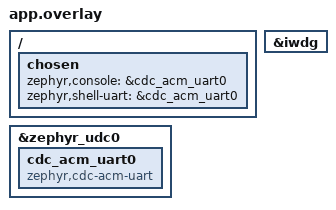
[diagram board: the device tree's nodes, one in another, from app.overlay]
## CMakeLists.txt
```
cmake_minimum_required(VERSION 3.20.0)

find_package(Zephyr REQUIRED HINTS $ENV{ZEPHYR_BASE})
project(my_zephyr_app)

target_sources(app PRIVATE src/watchdogtimer_event.c)
```

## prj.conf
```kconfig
CONFIG_LOG=y
CONFIG_ZBUS_LOG_LEVEL_INF=y

CONFIG_THREAD_NAME=y

CONFIG_USB_DEVICE_STACK=y
CONFIG_USB_DEVICE_INITIALIZE_AT_BOOT=y
CONFIG_SERIAL=y
CONFIG_CONSOLE=y

CONFIG_UART_CONSOLE=y
CONFIG_UART_LINE_CTRL=y
CONFIG_ZBUS=y
CONFIG_WATCHDOG=y
CONFIG_TASK_WDT=y
CONFIG_TASK_WDT_CHANNELS=3
CONFIG_LOG_RATELIMIT=y
CONFIG_LOG_RATELIMIT_INTERVAL_MS=1000

CONFIG_SHELL=y
CONFIG_KERNEL_SHELL=y

CONFIG_THREAD_MONITOR=y
CONFIG_THREAD_NAME=y
# Enable DTR check so shell waits for terminal to connect
CONFIG_SHELL_BACKEND_SERIAL_CHECK_DTR=y
CONFIG_TRACING=y
CONFIG_TRACING_CTF=y
CONFIG_TRACING_ASYNC=y
CONFIG_TRACING_BACKEND_RAM=y
```

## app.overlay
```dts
/{
	chosen {
	zephyr,console = &cdc_acm_uart0;
        zephyr,shell-uart =&cdc_acm_uart0;
	};
};

&zephyr_udc0{
	status="okay";
	cdc_acm_uart0: cdc_acm_uart0{
	compatible ="zephyr,cdc-acm-uart";
	};
};
&iwdg {
    status = "okay";
};
```

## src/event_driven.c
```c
#include<zephyr/kernel.h>
#include<zephyr/logging/log.h>
#include<zephyr/zbus/zbus.h>


LOG_MODULE_REGISTER(task4,LOG_LEVEL_INF);

#define STACK_SIZE        2048U
#define SENSOR_PERIOD_MS   100U
#define SENSOR_COUNT       18
#define TEMP_ALARM_MC   27000

struct sensor_data{
    int32_t temperature_mc;
    int32_t timestamp_ms;
};

static void display_listener_cb(const struct zbus_channel *chan);
/*listener*/
ZBUS_LISTENER_DEFINE(display_lis,display_listener_cb);
/*for the slow logging*/
ZBUS_SUBSCRIBER_DEFINE(alarm_sub,9);
ZBUS_CHAN_DEFINE(sensor_chan,
    struct sensor_data,
    NULL,
    NULL,
    ZBUS_OBSERVERS(display_lis,alarm_sub),
    ZBUS_MSG_INIT(.temperature_mc=0,
        .timestamp_ms=0,
    ));
static void display_listener_cb(const struct zbus_channel *chan){
    const struct sensor_data *msg= (const struct sensor_data *)zbus_chan_const_msg(chan);

   LOG_INF("[DISPLAY-LIS] thread=%s  temp=%d mC",
            k_thread_name_get(k_current_get()),
            msg->temperature_mc);
    
}

static void sensor_thread_fn(void *p1,void *p2,void *p3){
    ARG_UNUSED(p1);ARG_UNUSED(p2);ARG_UNUSED(p3);
    k_thread_name_set(k_current_get(),"sensor");
 for (int i = 0; i < SENSOR_COUNT; i++) {
        struct sensor_data data = {
            .temperature_mc = 24000 + (i * 350),
            .timestamp_ms = k_uptime_get_32(),
        };

        LOG_INF("[SENSOR] publish  temp=%d mC",
                data.temperature_mc);

        int ret = zbus_chan_pub(&sensor_chan, &data, K_MSEC(100));
        if (ret != 0) {
            LOG_WRN("[SENSOR] publish failed ret=%d", ret);
        }

        k_msleep(SENSOR_PERIOD_MS);
    }

    LOG_INF("[SENSOR] done");
}

/*sensor alarm**/

static void alarm_thread_fn(void *p1,void *p2,void *p3){
    ARG_UNUSED(p1);ARG_UNUSED(p2);ARG_UNUSED(p3);
    k_thread_name_set(k_current_get(),"alarm");
    const struct zbus_channel*chan=NULL;
    int alarms=0;
    while(true){
      int ret = zbus_sub_wait(&alarm_sub, &chan, K_MSEC(3000));
        if (ret != 0) {
            LOG_INF("[ALARM-SUB] timeout, done");
            break;
        }

        struct sensor_data msg;

        ret = zbus_chan_read(chan, &msg, K_MSEC(100));
        if (ret != 0) {
            LOG_WRN("[ALARM-SUB] read failed ret=%d", ret);
            continue;
        }

        if (msg.temperature_mc >= TEMP_ALARM_MC) {
            alarms++;

            LOG_WRN("[ALARM-SUB] HIGH TEMP  temp=%d mC alarms=%d",
                    msg.temperature_mc,
                    alarms);
        } else {
            LOG_INF("[ALARM-SUB] ok temp=%d mC",
                    msg.temperature_mc);
        }  
      }
}
K_THREAD_DEFINE(sensor_thread, STACK_SIZE, sensor_thread_fn,
                NULL, NULL, NULL, 5, 0, 0);


K_THREAD_DEFINE(alarm_thread, STACK_SIZE, alarm_thread_fn,
                NULL, NULL, NULL, 6, 0, 0);
                int main(void)
{
    LOG_INF("=== L4 Demo 2: Zbus Pub-Sub ===");
    LOG_INF("sensor publishes every %dms", SENSOR_PERIOD_MS);
    LOG_INF("display listener runs in publisher context");
    LOG_INF("logger uses message subscriber copies");
    LOG_INF("alarm uses a regular subscriber");
    LOG_INF("alarm threshold: %d mC", TEMP_ALARM_MC);

    return 0;
}
```

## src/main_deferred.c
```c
#include<zephyr/kernel.h>
#include<zephyr/logging/log.h>

LOG_MODULE_REGISTER(task3_work1,LOG_LEVEL_INF);
#define STACK_SIZE 1024U
#define SENSOR_MS 100U

static void sensor_work_handler(struct k_work *work){
    LOG_INF("WORK HANDLER EXCUTED,EVENT HAPPEND");
}
K_WORK_DEFINE(sensor_work,sensor_work_handler);
static void sensor_sim_fn(void *p1,void *p2,void *p3){
    while(1){
        LOG_INF("SENSOR FIRED :SUMMBITING THE WORK TO THE SYSTEM WORKQUEUE");
        k_work_submit(&sensor_work);
        /*
        k_work_reschedule(&sensor_debounce_work, K_MSEC(20));
        */
        k_msleep(SENSOR_MS);
    }
}
K_THREAD_DEFINE(sensor_thread, STACK_SIZE, sensor_sim_fn, NULL, NULL, NULL, 5, 0, 0);

int main(void) {
    LOG_INF("=== L3 Homework: Workqueue Solution ===");
    return 0;
}
```

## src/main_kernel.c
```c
#include<zephyr.h>
#include <zephyr/kernel.h>
#include <zephyr/logging/log.h>

LOG_MODULE_REGISTER(demo_kernel, LOG_LEVEL_INF);

#define STACK_SIZE 1024

#define PRIO_A 7
#define PRIO_B 5
#define PRIO_C 3
#define PRIO_D -1
void t_low_fn(void *p1, void *p2, void *p3)
{
    while (1) {
        LOG_INF("T_LOW RUNNING");
        k_msleep(300);
    }
}

void t_med_fn(void *p1, void *p2, void *p3)
{
    while (1) {
        LOG_INF("T_MED_RUNNING");
        k_msleep(200);
    }
}
void t_high_fn(void *p1, void *p2, void *p3)
{
    while (1) {
        LOG_INF("T_HIGH_RUNNING");
        k_msleep(100);
    }
}

void t_cooperative_fn(void *p1,void *p2,void *p3){
    while(1){
        int count=0;
        while(count<=5){
            LOG_INF("T_COOPERATIVE_RUNNING");
            count++;
        }
     LOG_INF("TASK COMPLETED BY THE COOPERATIVE THREAD");
     k_yield();

    }
}
/***
 *  when k_yield() is called, the scheduler looks for another "Ready" thread of equal or higher priority to hand the CPU to.
 *  Since -1 is the highest priority in your system, it instantly hands the CPU right back to
 *  the cooperative thread, locking up the system
 */
K_THREAD_DEFINE(thread_a, STACK_SIZE, t_low_fn,
                NULL, NULL, NULL, PRIO_A, 0, 0);
K_THREAD_DEFINE(thread_b, STACK_SIZE, t_med_fn,
                NULL, NULL, NULL, PRIO_B, 0, 0);
K_THREAD_DEFINE(thread_c,STACK_SIZE,t_high_fn,
                NULL,NULL,NULL,PRIO_C,0,0);
K_THREAD_DEFINE(thread_d,STACK_SIZE,t_cooperative_fn,
                NULL,NULL,NULL,PRIO_D,0,0);

int main(void){  
    LOG_INF("MAIN BOOT:RTOS SCHEDULER HAS STARTED !");

    return 0;
}
```

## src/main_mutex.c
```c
#include <zephyr/kernel.h>
#include <zephyr/logging/log.h>

LOG_MODULE_REGISTER(race_demo,LOG_LEVEL_INF);

int bank_balance=100;
K_MUTEX_DEFINE(bank_mutex);
void thread_a_entry(void){
    while(1){
        k_mutex_lock(&bank_mutex,K_FOREVER);

        LOG_INF("Thread A :READING BALANCE");
        int local_copy = bank_balance;
        local_copy = local_copy+50;
        k_msleep(100);
        bank_balance =local_copy;
        LOG_INF("THREAD A : DEPOSITED 50 ,FINAL BALANCE %d",bank_balance);
        k_mutex_unlock(&bank_mutex);
        k_msleep(2000);
    }
}

void thread_b_entry(void){
    while(1){
        k_msleep(50);
        k_mutex_lock(&bank_mutex,K_FOREVER);
        LOG_WRN("THREAD B : READING BALANCE....");
        int local_copy =bank_balance;
        local_copy=local_copy+20;
        bank_balance=local_copy;
        LOG_WRN("Thread B: Deposited $20. Final Balance: $%d", bank_balance);
        k_mutex_unlock(&bank_mutex);
        k_msleep(2000);
    }
}

K_THREAD_DEFINE(tid_a,1024,thread_a_entry,NULL,NULL,NULL,7,0,0);
K_THREAD_DEFINE(tid_b,1024,thread_b_entry,NULL,NULL,NULL,7,0,0);

int main(void){
    return 0;
}
```

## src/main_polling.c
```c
#include <zephyr/logging/log.h>
#include <stdbool.h>

LOG_MODULE_REGISTER(task3,LOG_LEVEL_INF);
K_SEM_DEFINE(my_sem,1,1);

#define STACK_SIZE 1024U
#define SENSOR_MS 100U
#define POLL_MS 10U
#define EVENT_COUNT 10U

static volatile bool sensor_flag = false;
static int wasted_wakeups = 0;

static void sensor_sim_fn(void *p1, void *p2,void *p3){
    while(1){
        k_sem_take(&my_sem,K_FOREVER);
        sensor_flag=true;
        k_sem_give(&my_sem);
        LOG_INF("THE FLAG IS SET AND SEM IS GIVEN");
        k_msleep(SENSOR_MS);
    }
}

static void polling_fn(void *p1, void *p2, void *p3) {
    bool current_flag;

    while(1) {
        /* Take semaphore to safely read and clear the flag */
        k_sem_take(&my_sem, K_FOREVER);
        
        current_flag = sensor_flag;
        if (current_flag == true) {
            sensor_flag = false;
        }
        
        /* ALWAYS give the semaphore back */
        k_sem_give(&my_sem);

        /* Process outside the lock to minimize blocking */
        if (current_flag) {
            LOG_INF("POLLING: Event processed. (Wasted wakeups since last event: %d)", wasted_wakeups);
            wasted_wakeups = 0;
        } else {
            wasted_wakeups++;
        }
        
        k_msleep(POLL_MS);
    }
}

K_THREAD_DEFINE(sensor_thread,  STACK_SIZE, sensor_sim_fn, NULL, NULL, NULL, 5, 0, 0);
K_THREAD_DEFINE(polling_thread, STACK_SIZE, polling_fn,    NULL, NULL, NULL, 5, 0, 0);int main(void)
{
    LOG_INF("=== L3 Homework: Polling to Workqueue ===");
    LOG_INF("Starter: polling every %dms, sensor fires every %dms",
            POLL_MS, SENSOR_MS);
    LOG_INF("Expected wasted wakeups: ~%d per event",
            (SENSOR_MS / POLL_MS) - 1);
    LOG_INF("Run this, count wakeups, then convert to workqueue.");

    /* Wait long enough for all events to complete */
    

    return 0;
}
```

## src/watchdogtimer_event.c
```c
#include <zephyr/kernel.h>
#include <zephyr/task_wdt/task_wdt.h>
#include <zephyr/drivers/watchdog.h>
#include <zephyr/logging/log.h>
#include <zephyr/zbus/zbus.h>
#include <zephyr/tracing/tracing.h>




LOG_MODULE_REGISTER(pipeline_test, LOG_LEVEL_INF); /* Added semicolon */

#define QUEUE_SIZE 8
#define WDT_TIMEOUT_MS 2000
#define DEADLINE_MS 50

struct pipeline_data {
    int value;
    uint32_t timestamps_ms;
};
K_MSGQ_DEFINE(consumer_queue, sizeof(struct pipeline_data), QUEUE_SIZE, 4);

void zbus_listener_callback(const struct zbus_channel *chan) {
    /* Bug 1 Fix: use zbus_chan_const_msg() directly — avoids corrupting the
     * pointer by passing &received_data (address of a pointer) into
     * zbus_chan_read(), which overwrote it with raw bytes causing
     * garbage latency (281162 ms) and corrupted SEQ numbers. */
    const struct pipeline_data *msg = zbus_chan_const_msg(chan);
    if (k_msgq_put(&consumer_queue, msg, K_NO_WAIT) != 0) {
        LOG_WRN("Consumer Inbox FULL! Dropping data: %d", msg->value);
    }
}
ZBUS_LISTENER_DEFINE(pipeline_listener, zbus_listener_callback);

ZBUS_CHAN_DEFINE(sensor_data_chan,
                 struct pipeline_data,
                 NULL,
                 NULL,
                 ZBUS_OBSERVERS(pipeline_listener), /* Fixed: Added 'S' */
                 ZBUS_MSG_INIT(0)
);

void wdt_callback(int channel_id, void *user_data) {
    LOG_ERR("FATAL: WATCHDOG TIMER EXPIRED, CHANNEL ID %d is unresponsive", channel_id);
    LOG_ERR("SYSTEM WILL NOW HARDWARE REBOOT");
}

void producer_thread(void) {
    struct pipeline_data data = { .value = 0,.timestamps_ms=0 };
    while(1) {
        data.timestamps_ms=k_uptime_get_32();
        zbus_chan_pub(&sensor_data_chan, &data, K_NO_WAIT);
        LOG_INF("event_ready seq= %d ,queue =%u", data.value,k_msgq_num_used_get(&consumer_queue));
        sys_trace_named_event("event_ready",data.value,k_msgq_num_used_get(&consumer_queue));
        data.value++;
        k_msleep(200);
    }
}

void consumer_thread(void) {
    struct pipeline_data data_in={0}; /* Fixed: struct typo */
    int process_count = 0;
    static uint32_t deadline_miss=0;

    int wdt_channel = task_wdt_add(WDT_TIMEOUT_MS, wdt_callback, NULL);
    if(wdt_channel < 0) {
        LOG_ERR("FAILED TO ADD TASK WDT CHANNEL");
        return;
    }
    
  while (1) {
        if (k_msgq_get(&consumer_queue, &data_in, K_MSEC(100)) == 0) {
            uint32_t latency_ms = k_uptime_get_32() - data_in.timestamps_ms;

            if (latency_ms > DEADLINE_MS) {
                deadline_miss++;
                LOG_WRN_RATELIMIT("deadline_miss count=%u, SEQ=%d, latency_ms=%u",
                                  deadline_miss, data_in.value, latency_ms);
            } else {
                LOG_INF("event_done seq=%d latency_ms=%u result=OK", 
                        data_in.value, latency_ms);
                        sys_trace_named_event("event_done", data_in.value, latency_ms);
                process_count++;
            }
        }

        /* Feed the watchdog to prove this thread is not frozen */
        task_wdt_feed(wdt_channel);

        /* SIMULATE A STUCK CONSUMER */
        if (process_count == 600) {
            LOG_WRN("Simulating a catastrophic consumer freeze...");
            k_msleep(10000); 
        }
    }
}

void health_thread(void) {
    while(1) {
        uint32_t used = k_msgq_num_used_get(&consumer_queue);
        if (used >= (QUEUE_SIZE * 3 / 4)) {
            LOG_WRN("QUEUE CAPACITY IS CRITICAL %d filled", used);
        }
        k_msleep(500);
    }
}

K_THREAD_DEFINE(prod_id, 1024, (k_thread_entry_t)producer_thread, NULL, NULL, NULL, 5, 0, 0);
K_THREAD_DEFINE(cons_id, 1024, (k_thread_entry_t)consumer_thread, NULL, NULL, NULL, 5, 0, 0);
K_THREAD_DEFINE(hlth_id, 1024, (k_thread_entry_t)health_thread, NULL, NULL, NULL, 4, 0, 0);

int main(void) {
    LOG_INF("STARTING THE ZBUS pipeline & watchdog test");
    const struct device *hw_wdt = DEVICE_DT_GET(DT_NODELABEL(iwdg));
    k_thread_name_set(prod_id, "producer");
    k_thread_name_set(cons_id, "consumer");
    k_thread_name_set(hlth_id, "health");
    if(!device_is_ready(hw_wdt)) {
        LOG_WRN("HARDWARE NOT READY, RUNNING TASK WDT IN SOFTWARE ONLY MODE");
        task_wdt_init(NULL);
    } else {
        task_wdt_init(hw_wdt);
    }
    return 0;
}
```
